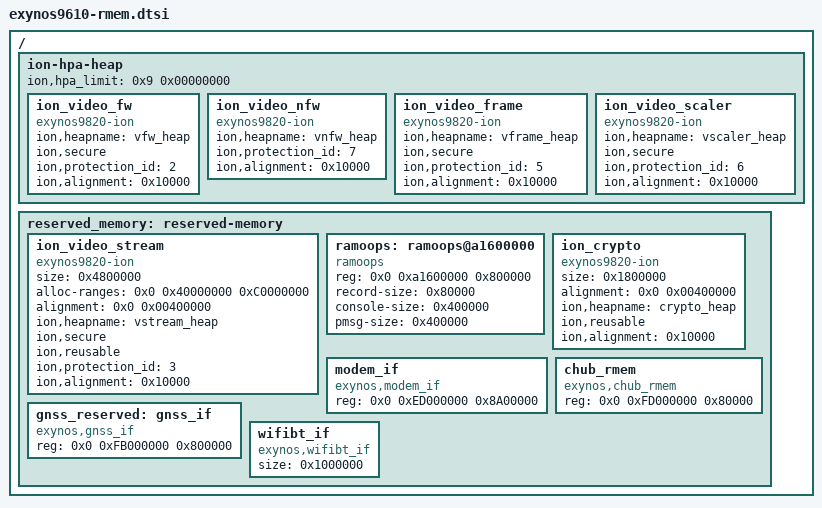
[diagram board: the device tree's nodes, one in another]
/*
 * SAMSUNG EXYNOS device tree source for reserved-memory
 *
 * Copyright (c) 2015 Samsung Electronics Co., Ltd.
 *		http://www.samsung.com
 *
 * This program is free software; you can redistribute it and/or modify
 * it under the terms of the GNU General Public License version 2 as
 * published by the Free Software Foundation.
 */

#include <generated/autoconf.h>
#include <dt-bindings/soc/samsung/debug-snapshot-table.h>
#include <dt-bindings/soc/samsung/exynos9610-seclog.h>

/ {
	ion-hpa-heap {
		#address-cells = <2>;
		#size-cells = <1>;
		ranges;
		ion,hpa_limit = <0x9 0x00000000>;
		ion_video_fw {
			compatible = "exynos9820-ion";
			ion,heapname = "vfw_heap";
			ion,secure;
			ion,protection_id = <2>;
			ion,alignment = <0x10000>;
		};

		ion_video_nfw {
			compatible = "exynos9820-ion";
			ion,heapname = "vnfw_heap";
			ion,protection_id = <7>;
			ion,alignment = <0x10000>;
		};

		ion_video_frame {
			compatible = "exynos9820-ion";
			ion,heapname = "vframe_heap";
			ion,secure;
			ion,protection_id = <5>;
			ion,alignment = <0x10000>;
		};

		ion_video_scaler {
			compatible = "exynos9820-ion";
			ion,heapname = "vscaler_heap";
			ion,secure;
			ion,protection_id = <6>;
			ion,alignment = <0x10000>;
		};
	};

	reserved_memory: reserved-memory {
		#address-cells = <2>;
		#size-cells = <1>;
		ranges;

		ion_video_stream {
			compatible = "exynos9820-ion";
			size = <0x4800000>;
			alloc-ranges = <0x0 0x40000000 0xC0000000>;
			alignment = <0x0 0x00400000>;
			ion,heapname = "vstream_heap";
			ion,secure;
			ion,reusable;
			ion,protection_id = <3>;
			ion,alignment = <0x10000>;
		};

		ramoops: ramoops@a1600000 {
			compatible = "ramoops";
			reg = <0x0 0xa1600000 0x800000>;
			record-size = <0x80000>;
			console-size = <0x400000>;
			pmsg-size = <0x400000>;
		};

		ion_crypto {
			compatible = "exynos9820-ion";
			size = <0x1800000>;
			alignment = <0x0 0x00400000>;
			ion,heapname = "crypto_heap";
			ion,reusable;
			ion,alignment = <0x10000>;
		};

		modem_if {
			compatible = "exynos,modem_if";
			reg = <0x0 0xED000000 0x8A00000>;
		};

		chub_rmem: chub_rmem {
			compatible = "exynos,chub_rmem";
			/* To dump SHUB SRAM out upon shub firmware crash */
			reg = <0x0 0xFD000000 0x80000>;
		};

		gnss_reserved: gnss_if {
			compatible = "exynos,gnss_if";
			reg = <0x0 0xFB000000 0x800000>;
		};

		wifibt_if {
			compatible = "exynos,wifibt_if";
			size = <0x1000000>; /* 16MB */
		};
	};
};
